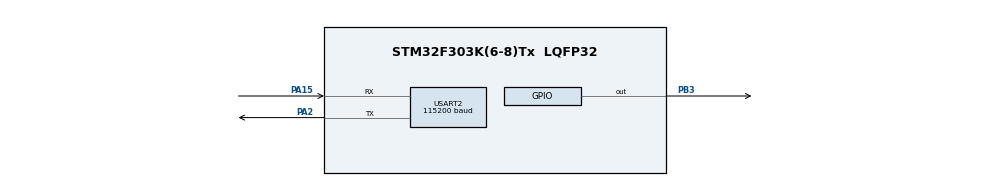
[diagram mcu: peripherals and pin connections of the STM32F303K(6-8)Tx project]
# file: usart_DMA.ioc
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Dma.Request0=USART2_RX
Dma.Request1=USART2_TX
Dma.USART2_RX.0.Direction=DMA_PERIPH_TO_MEMORY
Dma.USART2_RX.0.Instance=DMA1_Channel6
Dma.USART2_RX.0.MemDataAlignment=DMA_MDATAALIGN_BYTE
Dma.USART2_RX.0.MemInc=DMA_MINC_ENABLE
Dma.USART2_RX.0.Mode=DMA_CIRCULAR
Dma.USART2_RX.0.PeriphDataAlignment=DMA_PDATAALIGN_BYTE
Dma.USART2_RX.0.PeriphInc=DMA_PINC_DISABLE
Dma.USART2_RX.0.Priority=DMA_PRIORITY_MEDIUM
Dma.USART2_TX.1.Direction=DMA_MEMORY_TO_PERIPH
Dma.USART2_TX.1.Instance=DMA1_Channel7
Dma.USART2_TX.1.MemDataAlignment=DMA_MDATAALIGN_BYTE
Dma.USART2_TX.1.MemInc=DMA_MINC_ENABLE
Dma.USART2_TX.1.Mode=DMA_NORMAL
Dma.USART2_TX.1.PeriphDataAlignment=DMA_PDATAALIGN_BYTE
Dma.USART2_TX.1.PeriphInc=DMA_PINC_DISABLE
Dma.USART2_TX.1.Priority=DMA_PRIORITY_MEDIUM
Mcu.Family=STM32F3
Mcu.Name=STM32F303K(6-8)Tx
Mcu.Package=LQFP32
NVIC.DMA1_Channel6_IRQn=true\:0\:0\:false\:false\:true\:false\:true
NVIC.DMA1_Channel7_IRQn=true\:0\:0\:false\:false\:true\:false\:true
NVIC.PriorityGroup=NVIC_PRIORITYGROUP_4
PA15.Mode=Asynchronous
PA15.Signal=USART2_RX
PA2.Mode=Asynchronous
PA2.Signal=USART2_TX
PB3.Signal=GPIO_Output
ProjectManager.HeapSize=0x200
ProjectManager.StackSize=0x400
ProjectManager.TargetToolchain=STM32CubeIDE
RCC.AHBFreq_Value=8000000
RCC.APB1Freq_Value=8000000
RCC.APB2Freq_Value=8000000
RCC.CortexFreq_Value=8000000
RCC.HSE_VALUE=8000000
RCC.HSI_VALUE=8000000
RCC.SYSCLKFreq_VALUE=8000000
USART2.BaudRate=115200
USART2.VirtualMode-Asynchronous=VM_ASYNC
board=custom

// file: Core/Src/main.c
/* USER CODE BEGIN Header */
/**
  ******************************************************************************
  * @file           : main.c
  * @brief          : Main program body
  ******************************************************************************
  * @attention
  *
  * <h2><center>&copy; Copyright (c) 2021 STMicroelectronics.
  * All rights reserved.</center></h2>
  *
  * This software component is licensed by ST under BSD 3-Clause license,
  * the "License"; You may not use this file except in compliance with the
  * License. You may obtain a copy of the License at:
  *                        opensource.org/licenses/BSD-3-Clause
  *
  ******************************************************************************
  */
/* USER CODE END Header */

#include "main.h"
#include "dma.h"
#include "usart.h"
#include "gpio.h"

void SystemClock_Config(void);
/* USER CODE BEGIN PFP */
void receive_dma_data(const uint8_t* data,uint16_t len);
/* USER CODE END PFP */

int main(void)
{

  /* MCU Configuration--------------------------------------------------------*/

  /* Reset of all peripherals, Initializes the Flash interface and the Systick. */

  LL_APB2_GRP1_EnableClock(LL_APB2_GRP1_PERIPH_SYSCFG);
  LL_APB1_GRP1_EnableClock(LL_APB1_GRP1_PERIPH_PWR);

  NVIC_SetPriorityGrouping(NVIC_PRIORITYGROUP_4);

  /* System interrupt init*/

  /* Configure the system clock */
  SystemClock_Config();

  /* Initialize all configured peripherals */
  MX_GPIO_Init();
  MX_DMA_Init();
  MX_USART2_UART_Init();
  /* USER CODE BEGIN 2 */
  USART2_RegisterCallback(receive_dma_data);//调用callback函数
  /* USER CODE END 2 */
 //uint8_t tx_data=0;
  /* Infinite loop */
  while (1)
  {
#if POLLING //轮询函数，定期查询是否收到数据。这里没有用中断。
	  USART2_CheckDmaReception();
	  LL_mDelay(10);
#else
	  USART2_PutBuffer(tx_data,sizeof(tx_data));
	  LL_mDelay(1000);
#endif
  }
}

void SystemClock_Config(void)
{
  LL_FLASH_SetLatency(LL_FLASH_LATENCY_0);

  if(LL_FLASH_GetLatency() != LL_FLASH_LATENCY_0)
  {
  Error_Handler();
  }
  LL_RCC_HSI_Enable();

   /* Wait till HSI is ready */
  while(LL_RCC_HSI_IsReady() != 1)
  {

  }
  LL_RCC_HSI_SetCalibTrimming(16);
  LL_RCC_SetAHBPrescaler(LL_RCC_SYSCLK_DIV_1);
  LL_RCC_SetAPB1Prescaler(LL_RCC_APB1_DIV_1);
  LL_RCC_SetAPB2Prescaler(LL_RCC_APB1_DIV_1);
  LL_RCC_SetSysClkSource(LL_RCC_SYS_CLKSOURCE_HSI);

   /* Wait till System clock is ready */
  while(LL_RCC_GetSysClkSource() != LL_RCC_SYS_CLKSOURCE_STATUS_HSI)
  {

  }
  LL_Init1msTick(8000000);
  LL_SYSTICK_SetClkSource(LL_SYSTICK_CLKSOURCE_HCLK);
  LL_SetSystemCoreClock(8000000);
}

void receive_dma_data(const uint8_t* data,uint16_t len)
{
	uint8_t count;
	for(uint8_t i =0;i<len;i++)
	{
		if(*(data+1)=='1')
		{
			count++;
		}
	}
}

void Error_Handler(void)
{
}

/************************ (C) COPYRIGHT STMicroelectronics *****END OF FILE****/
